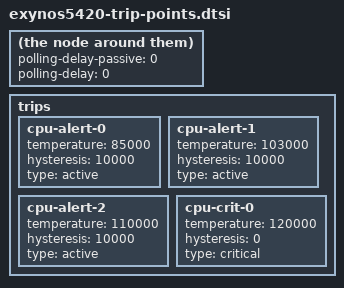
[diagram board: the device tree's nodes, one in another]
polling-delay-passive = <0>;
polling-delay = <0>;
trips {
	cpu-alert-0 {
		temperature = <85000>;  
		hysteresis = <10000>;  
		type = "active";
	};
	cpu-alert-1 {
		temperature = <103000>;  
		hysteresis = <10000>;  
		type = "active";
	};
	cpu-alert-2 {
		temperature = <110000>;  
		hysteresis = <10000>;  
		type = "active";
	};
	cpu-crit-0 {
		temperature = <120000>;  
		hysteresis = <0>;  
		type = "critical";
	};
};
